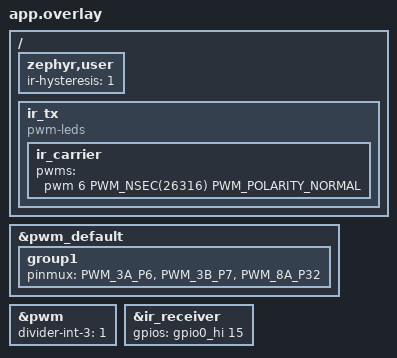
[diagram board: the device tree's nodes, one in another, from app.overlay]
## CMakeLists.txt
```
cmake_minimum_required(VERSION 3.20.0)
find_package(Zephyr REQUIRED HINTS $ENV{ZEPHYR_BASE})
project(ir_capture)
target_sources(app PRIVATE src/main.c src/ir_decode.c src/ir_seq.c src/ui.c
  src/slot_store.c)
```

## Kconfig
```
# Opcoes proprias do app. O resto do Kconfig vem do Zephyr.

mainmenu "zbook remote control"

config APP_IR_DEBUG
	bool "Imprimir toda captura IR no console"
	help
	  Imprime cada captura do receptor, dentro ou fora do modo gravar:
	  instante da primeira borda, intervalo desde a captura anterior,
	  duracoes brutas e o resultado de cada quadro decodificado
	  separadamente, com o tempo de decodificacao na placa.
	  Serve para diagnosticar controles que mandam varios quadros por
	  toque. A 115200 baud, a impressao trava o main por ~25 ms numa
	  captura tipica e ate ~130 ms numa de 200 bordas. Desligada, o
	  codigo nao vai para o binario.

config APP_IR_ROBUST_FALLBACK
	bool "Decodificador IR robusto como reserva do convencional"
	default y
	help
	  O decodificador tenta primeiro o caminho convencional (tempos
	  conferidos um a um, para o sinal limpo do receptor sem o
	  capacitor de 100 nF). Com esta opcao, um quadro que ele nao le
	  vai para o caminho robusto (blocos, esticamento e busca), feito
	  para o sinal distorcido. Desligada, so o convencional roda; serve
	  para comparar os dois sem mexer no codigo. A busca do robusto
	  precisa de CONFIG_MAIN_STACK_SIZE=8192.

source "Kconfig.zephyr"
```

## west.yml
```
manifest:
  remotes:
    - name: zephyrproject-rtos
      url-base: https://github.com/zephyrproject-rtos
    - name: zephyr-book
      url-base: https://github.com/zephyr-book
  projects:
    - name: zephyr
      remote: zephyrproject-rtos
      revision: 03b0b5443c7a760745826cc53c40e1986d753f86
      import: true
    - name: zbook
      remote: zephyr-book
      revision: 530df5dc6e51823b0eafb1f639ce86da6029fa8f
      path: modules/zbook
  self:
    path: zbook_remote_control
```

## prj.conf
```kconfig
CONFIG_GPIO=y
CONFIG_PWM=y
CONFIG_INPUT=y
CONFIG_LOG_PRINTK=n
# A busca do decodificador e recursiva (ate 33 niveis) e guarda as
# hipoteses de cada bloco na pilha: ~4 KB no pior caso.
CONFIG_MAIN_STACK_SIZE=8192

# Display OLED (SSD1306 por I2C) com o framebuffer de caracteres (CFB).
# A CFB aloca o buffer da tela (128 * 64 / 8 = 1 KB) com k_malloc.
CONFIG_DISPLAY=y
CONFIG_CHARACTER_FRAMEBUFFER=y
CONFIG_HEAP_MEM_POOL_SIZE=4096

# Slots na flash: subsistema settings com NVS na particao storage
# (zephyr,settings-partition da placa, ultimos 256 KB).
CONFIG_FLASH=y
CONFIG_FLASH_MAP=y
CONFIG_NVS=y
CONFIG_SETTINGS=y
CONFIG_SETTINGS_NVS=y
# Gravacoes cruas tem ate ~2 KB: 32 setores de 4 KB (128 KB dos 256 KB da
# particao). O NVS precisa de um setor livre para a coleta de lixo.
CONFIG_SETTINGS_NVS_SECTOR_COUNT=32

# Imprime toda captura IR (ver Kconfig). Para ligar sem mexer aqui:
#   west build -b zbook/rp2350b/m33 . -- -DCONFIG_APP_IR_DEBUG=y
CONFIG_APP_IR_DEBUG=n

# Caminho robusto do decodificador como reserva (ver Kconfig). Para
# comparar so com o convencional:
#   west build -b zbook/rp2350b/m33 . -- -DCONFIG_APP_IR_ROBUST_FALLBACK=n
CONFIG_APP_IR_ROBUST_FALLBACK=y
```

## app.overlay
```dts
/* Emissor IR no GPIO6 via PWM (slice 3, canal A) para gerar 38 kHz.
 * Vale para a ZBook P2. */

/* O GPIO6 deixa de ser um LED comum e passa a ser controlado pelo PWM. */
/delete-node/ &ir_emitter;

/* Conecta o GPIO6 ao PWM, mantendo os pinos que a placa ja usava. */
&pwm_default {
	group1 {
		pinmux = <PWM_3A_P6>, <PWM_3B_P7>, <PWM_8A_P32>;
	};
};

/* Divisor 1 no slice 3: o contador anda a 150 MHz, o que da
 * resolucao fina para os 38 kHz. */
&pwm {
	divider-int-3 = <1>;
};

/* Configuracao do pino do receptor (GPIO47). Variacoes testadas na
 * Parte A (docs/DEVLOG.md): sem pull, GPIO_PULL_UP e GPIO_PULL_DOWN. O
 * pull-down ficou porque dava o menor esticamento dos pulsos (~850 us).
 * Esse esticamento nao era do receptor: vinha de um capacitor de 100 nF
 * na linha, que nao devia estar ali. Sem o capacitor, fica entre 0 e
 * 20 us e o decodificador usa o caminho convencional; o caminho robusto
 * ficou como reserva. O pull-down foi mantido (nao foi medido de novo
 * sem o capacitor). */
&ir_receiver {
	gpios = <&gpio0_hi 15 (GPIO_ACTIVE_HIGH | GPIO_PULL_DOWN)>;
};

/ {
	/* Propriedades proprias da aplicacao, lidas no main.c com DT_PROP.
	 * ir-hysteresis: 1 liga o schmitt trigger do pino do receptor (padrao
	 * do RP2350), 0 desliga. O driver GPIO do Zephyr nao tem flag para
	 * isso, entao o main.c aplica o valor pelo Pico SDK. Desligada, a
	 * borda lenta do receptor gera bordas espurias e nenhum toque foi
	 * capturado; por isso fica ligada. (Medido com o capacitor de
	 * 100 nF na linha, que provavelmente deixava a borda lenta; sem ele,
	 * nao foi testado de novo.) */
	zephyr,user {
		ir-hysteresis = <1>;
	};

	ir_tx {
		compatible = "pwm-leds";

		/* Canal 6 = slice 3, canal A (GPIO6). Periodo de 26316 ns = 38 kHz. */
		ir_carrier: ir_carrier {
			pwms = <&pwm 6 PWM_NSEC(26316) PWM_POLARITY_NORMAL>;
		};
	};
};
```

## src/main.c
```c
#include <string.h>

#include <zephyr/drivers/gpio.h>
#include <zephyr/drivers/pwm.h>
#include <zephyr/kernel.h>

/* API do Pico SDK (hal_rpi_pico), usada so para a histerese do pino,
 * que o driver GPIO do Zephyr nao expoe. */
#include <hardware/gpio.h>
#include <hardware/structs/pads_bank0.h>

#include "ir_decode.h"
#include "ir_edges.h"
#include "ir_seq.h"
#include "slot_store.h"
#include "ui.h"

/* Bordas por captura. Um quadro NEC tem 68; ar-condicionado chega a
 * centenas (gravacao crua). */
#define MAX_EDGES IR_RAW_MAX

/* Mais quadros que isso numa captura sao ignorados (MAX_EDGES cabe ~3). */
#define MAX_FRAMES 8

/* Silencio que encerra uma captura. Menor que o intervalo entre os
 * quadros de um toque (~46 ms), para cada quadro chegar separado. */
#define END_OF_CAPTURE_MS 20

/* 1 imprime as duracoes brutas de cada captura no modo gravar. Com
 * CONFIG_APP_IR_DEBUG, elas saem sempre, na impressao de depuracao. */
#define PRINT_RAW 1

/* Histerese (schmitt trigger) do pino do receptor, escolhida no
 * app.overlay pela propriedade ir-hysteresis do no zephyr,user. O padrao
 * do RP2350 apos o reset e ligada. */
#define ZEPHYR_USER DT_PATH(zephyr_user)
#define IR_HYSTERESIS DT_PROP_OR(ZEPHYR_USER, ir_hysteresis, 1)

/* Receptor (entrada) e portadora do emissor (saida). */
static const struct gpio_dt_spec ir =
    GPIO_DT_SPEC_GET(DT_NODELABEL(ir_receiver), gpios);
static const struct pwm_dt_spec carrier =
    PWM_DT_SPEC_GET(DT_NODELABEL(ir_carrier));
static struct gpio_callback ir_cb;

/* Captura: preenchido pela interrupcao, pelo filtro do ir_edges.h, que
 * le o nivel do pino e apaga os intervalos da portadora. */
static volatile uint32_t edges[MAX_EDGES];
static struct ir_edges cap = {.t = edges, .max = MAX_EDGES};
static volatile uint32_t last_edge;
static uint32_t ir_pin; /* numero absoluto do pino (GPIO47) */
static uint32_t copy[MAX_EDGES];
static uint32_t durations[MAX_EDGES];

/* Junta os quadros de um toque numa sequencia (ir_seq.c). So os codigos
 * vao para os slots; os tempos sao remontados na hora de enviar. */
static struct ir_recorder rec;

/* Transmissao montada a partir da sequencia ou da gravacao crua. */
#define TX_MAX (IR_SEQ_TX_MAX > IR_RAW_MAX ? IR_SEQ_TX_MAX : IR_RAW_MAX)
static uint32_t tx_buf[TX_MAX];

/* Copia da gravacao crua pronta (grande demais para a pilha). */
static struct ir_raw raw_done;

/* Resultado de um quadro, guardado para a impressao de depuracao. */
struct frame_result {
  struct ir_span span;
  enum ir_status status;
  struct ir_code code;
  struct ir_decode_info info;
  uint32_t t_us;      /* inicio do quadro (primeira borda) */
  uint32_t decode_us; /* tempo do ir_decode_frame na placa */
};

static void on_edge(const struct device *dev, struct gpio_callback *cb,
                    uint32_t pins) {
  uint32_t now = k_cycle_get_32();

  /* Leitura direta do SIO (inline, poucos ciclos). */
  ir_edges_on_edge(&cap, now, gpio_get(ir_pin));
  last_edge = now;
}

/* Reproduz um sinal: nos pulsos liga a portadora (duty ~1/3),
 * nos espacos desliga. */
static void ir_send(const uint32_t *dur_us, int count) {
  /* Sem isso, o proprio receptor da placa capturaria o envio. */
  gpio_pin_interrupt_configure_dt(&ir, GPIO_INT_DISABLE);

  /* Evita que outra thread interrompa o envio no meio. */
  k_sched_lock();

  uint32_t t = k_cycle_get_32();

  for (int i = 0; i < count; i++) {
    bool pulse = (i % 2) == 0;

    pwm_set_pulse_dt(&carrier, pulse ? carrier.period / 3 : 0);

    /* Espera ate o instante exato do fim deste intervalo.
     * Usar um alvo absoluto evita acumular atraso. */
    t += k_us_to_cyc_ceil32(dur_us[i]);
    while ((int32_t)(k_cycle_get_32() - t) < 0) {
    }
  }
  pwm_set_pulse_dt(&carrier, 0);

  k_sched_unlock();

  /* Descarta o que tiver sido capturado e volta a escutar. */
  k_msleep(50);
  cap.n = 0;
  gpio_pin_interrupt_configure_dt(&ir, GPIO_INT_EDGE_BOTH);
}

/* Se a captura terminou (silencio de END_OF_CAPTURE_MS), copia as bordas
 * para out e devolve quantas sao; senao devolve 0.
 *
 * Tudo acontece com as interrupcoes travadas. Antes, o relogio era lido
 * primeiro e last_edge depois; se uma borda chegasse entre as duas
 * leituras, last_edge ficava maior que o "agora", a subtracao sem sinal
 * dava ~4 bilhoes e a captura era encerrada no meio do quadro. Com
 * irq_lock, on_edge nao roda entre as leituras, entao agora >= last_edge,
 * e a decisao de encerrar e a copia ficam consistentes: nenhuma borda
 * nova entra depois da decisao. */
static int take_capture(uint32_t *out) {
  int n = 0;
  unsigned int key = irq_lock();
  uint32_t idle = k_cycle_get_32() - last_edge;

  if (cap.n > 0 && k_cyc_to_ms_floor32(idle) >= END_OF_CAPTURE_MS) {
    n = cap.n;
    for (int i = 0; i < n; i++) {
      out[i] = edges[i];
    }
    cap.n = 0;
  }
  irq_unlock(key);
  return n;
}

/* Relogio do gravador: us de 32 bits, tirado do contador de ciclos de
 * 64 bits (da a volta a cada ~71 min, sem salto). */
static uint32_t now_us(void) {
  return (uint32_t)k_cyc_to_us_floor64(k_cycle_get_64());
}

/* Instante de uma borda no relogio do gravador. A interrupcao guarda so
 * os 32 bits de baixo do contador (que da a volta a cada ~28 s); a idade
 * da borda, medida contra o mesmo "agora", reconstroi os 64 bits. Assim
 * vale o horario em que o sinal chegou, nao a hora em que o main viu a
 * captura (que atrasa com o desenho da tela ou um printk). */
static uint32_t edge_time_us(uint32_t edge_cyc, uint64_t now_cyc) {
  uint32_t age = (uint32_t)now_cyc - edge_cyc;

  return (uint32_t)k_cyc_to_us_floor64(now_cyc - age);
}

/* Envia a sequencia de um slot gravado, com "Enviando..." na tela. */
static void send_slot(int slot) {
  const struct ir_seq *seq = ui_slot_sequence(slot);
  const uint16_t *raw;
  int raw_n = ui_slot_raw(slot, &raw);

  if (raw_n > 0 && raw_n <= (int)ARRAY_SIZE(tx_buf)) {
    uint32_t total = 0;

    for (int i = 0; i < raw_n; i++) {
      tx_buf[i] = raw[i];
      total += raw[i];
    }
    printk("Enviando \"%s / %s\" (%s, %d intervalos, %u ms)\n",
           ui_device_name(ui_device()), ui_slot_name(slot),
           ui_slot_source(slot) == UI_SRC_RECORDED ? "gravacao crua"
                                                   : "de fabrica",
           raw_n, total / 1000);
    ui_set_sending(slot);
    ui_draw();
    ir_send(tx_buf, raw_n);
    ui_set_sending(-1);
    printk("Enviado\n\n");
    return;
  }
  if (seq == NULL) {
    return;
  }
  int n = ir_seq_encode(seq, tx_buf, ARRAY_SIZE(tx_buf));

  if (n == 0) {
    printk("Slot \"%s\": sequencia invalida, nada enviado\n",
           ui_slot_name(slot));
    return;
  }
  printk("Enviando \"%s / %s\" (%s, %d codigo(s)):\n",
         ui_device_name(ui_device()), ui_slot_name(slot),
         ui_slot_source(slot) == UI_SRC_RECORDED ? "gravado" : "de fabrica",
         seq->count);
  for (int i = 0; i < seq->count; i++) {
    printk("  %s 0x%08X (+%u us)\n", ir_protocol_name(seq->codes[i].protocol),
           seq->codes[i].code, seq->gap_us[i]);
  }
  /* ir_send trava o escalonador, entao a tela e desenhada antes. */
  ui_set_sending(slot);
  ui_draw();
  ir_send(tx_buf, n);
  ui_set_sending(-1);
  printk("Enviado\n\n");
}

static void print_durations(const uint32_t *dur, int n) {
  printk("Bruto: %d intervalos\n", n);
  for (int i = 0; i < n; i++) {
    printk("%c%u ", (i % 2) ? '-' : '+', dur[i]);
    if ((i + 1) % 8 == 0) {
      printk("\n");
    }
  }
  printk("\n");
}

/* Mostra no console o que o gravador fez com um quadro. */
static void report_frame(const struct frame_result *f,
                         enum ir_rec_result r) {
  const struct ir_seq *seq = &rec.seq;

  switch (r) {
  case IR_REC_ADDED:
    printk("Gravado: %s 0x%08X (codigo %d, +%u us)\n",
           ir_protocol_name(f->code.protocol), f->code.code, seq->count,
           seq->gap_us[seq->count - 1]);
    break;
  case IR_REC_PENDING:
    printk("Quadro %s 0x%08X com pulso perdido: esperando confirmacao\n",
           ir_protocol_name(f->code.protocol), f->code.code);
    break;
  case IR_REC_CYCLE:
    printk("Codigo 0x%08X ja esta na sequencia (controle recomecou): "
           "ignorado\n", f->code.code);
    break;
  case IR_REC_FULL:
    printk("Sequencia cheia (%d codigos): 0x%08X ignorado\n", IR_SEQ_MAX,
           f->code.code);
    break;
  case IR_REC_LATE:
    printk("Quadro 0x%08X comecou depois da janela: ignorado\n",
           f->code.code);
    break;
  case IR_REC_REJECTED:
    printk("Quadro rejeitado: %s\n", ir_status_name(f->status));
    break;
  case IR_REC_SAME:
  case IR_REC_REPEAT:
    break;
  }
}

/* Impressao de depuracao de toda captura, com ou sem modo gravar
 * (CONFIG_APP_IR_DEBUG). Feita depois do gravador, para nao atrasar
 * nada que dependa de tempo; o gravador usa o horario das bordas. */
static void debug_capture(int n_edges_copied, int n, const struct frame_result *fr,
                          int frames, uint32_t t0_us) {
  static uint32_t count;
  static uint32_t prev_t0_us;
  static uint32_t prev_end_us;
  uint32_t end_us = t0_us + k_cyc_to_us_floor32(copy[n_edges_copied - 1] - copy[0]);

  count++;
  printk("== IR captura %u: t=%u ms", count, t0_us / 1000);
  if (count > 1) {
    printk(", +%u ms desde a anterior (silencio %u ms)",
           (t0_us - prev_t0_us) / 1000, (t0_us - prev_end_us) / 1000);
  }
  printk(", modo gravar: %s\n", ui_is_recording() ? "sim" : "nao");
  printk("Limite MAX_EDGES (%d bordas): %s\n", MAX_EDGES,
         n_edges_copied >= MAX_EDGES ? "SIM, captura cortada" : "nao");
  printk("Filtro: %u espacos de portadora apagados, %u bordas fora de "
         "ordem ignoradas (desde a partida)\n", cap.merged, cap.ignored);
  prev_t0_us = t0_us;
  prev_end_us = end_us;

  print_durations(durations, n);
  for (int f = 0; f < frames; f++) {
    const struct frame_result *r = &fr[f];

    printk("quadro %d: %d intervalos, +%u us: ", f + 1, r->span.len,
           r->t_us - t0_us);
    if (r->status == IR_OK) {
      printk("%s 0x%08X, esticamento %d us (%d a %d), pulsos perdidos %d",
             ir_protocol_name(r->code.protocol), r->code.code,
             r->info.stretch_avg_us, r->info.stretch_min_us,
             r->info.stretch_max_us, r->info.lost_pulses);
      printk(", %d passos, caminho %s", r->info.search_steps,
             r->info.path == IR_PATH_CONVENTIONAL ? "convencional"
                                                  : "robusto");
    } else {
      printk("%s", ir_status_name(r->status));
    }
    printk(", decodificado em %u us\n", r->decode_us);
  }
  printk("\n");
}

/* Separa a captura em quadros, decodifica cada um e entrega ao gravador.
 * O ir_decode para no primeiro quadro valido; aqui cada quadro conta,
 * porque se o main atrasar dois codigos diferentes podem cair na mesma
 * captura. */
static void handle_capture(int n_edges_copied) {
  static struct frame_result fr[MAX_FRAMES];
  struct ir_span spans[MAX_FRAMES];
  int n = n_edges_copied - 1;
  uint64_t now_cyc = k_cycle_get_64();
  bool recording = ui_is_recording();
  bool debug = IS_ENABLED(CONFIG_APP_IR_DEBUG);

  if (!recording && !debug) {
    return;
  }

  /* Converte instantes em duracoes: pulso, espaco, pulso... */
  for (int i = 0; i < n; i++) {
    durations[i] = k_cyc_to_us_floor32(copy[i + 1] - copy[i]);
  }
  if (PRINT_RAW && recording && !debug) {
    print_durations(durations, n);
  }

  int frames = ir_split_frames(durations, n, spans, MAX_FRAMES);

  for (int f = 0; f < frames; f++) {
    struct frame_result *r = &fr[f];
    uint32_t c0 = k_cycle_get_32();

    r->span = spans[f];
    r->status = ir_decode_frame(durations + spans[f].start, spans[f].len,
                                &r->code, &r->info);
    r->decode_us = k_cyc_to_us_floor32(k_cycle_get_32() - c0);
    /* durations[i] comeca na borda copy[i]. */
    r->t_us = edge_time_us(copy[spans[f].start], now_cyc);

    if (recording) {
      enum ir_rec_result res = ir_rec_frame(
          &rec, r->status, &r->code,
          r->status == IR_OK ? r->info.lost_pulses : 0, r->t_us);

      if (!debug && r->status == IR_OK) {
        printk("Quadro: %s 0x%08X, esticamento %d us (%d a %d), "
               "pulsos perdidos %d\n",
               ir_protocol_name(r->code.protocol), r->code.code,
               r->info.stretch_avg_us, r->info.stretch_min_us,
               r->info.stretch_max_us, r->info.lost_pulses);
      }
      report_frame(r, res);
    }
  }

  /* A captura inteira vai para a gravacao crua, que so vale se nenhum
   * codigo for reconhecido no toque. */
  if (recording) {
    ir_rec_capture(&rec, durations, n, edge_time_us(copy[0], now_cyc),
                   n_edges_copied >= MAX_EDGES);
  }
  if (debug) {
    debug_capture(n_edges_copied, n, fr, frames,
                  edge_time_us(copy[0], now_cyc));
  }
}

/* Confere o gravador: aviso de falha adiado e fim da janela. */
static void poll_recorder(void) {
  struct ir_seq seq;
  bool suspect = false;

  switch (ir_rec_poll(&rec, now_us(), &seq, &suspect)) {
  case IR_REC_POLL_WARN:
    printk("Aviso: sinal nao reconhecido (%s); nada foi gravado.\n"
           "Tente de novo com o controle a uns 30 cm a 1 m da placa.\n\n",
           rec.warn_reason);
    ui_record_failed();
    break;

  case IR_REC_POLL_DONE: {
    int slot = ui_record_sequence(&seq);

    if (slot < 0) {
      break;
    }
    printk("Slot \"%s\" gravado com %d codigo(s)\n", ui_slot_name(slot),
           seq.count);
    if (suspect) {
      printk("Aviso: um quadro perto deste toque falhou; a sequencia pode "
             "estar incompleta.\nSe o aparelho nao reagir, grave de novo.\n");
    }
    int err = slot_store_save(ui_device(), slot, &seq);

    if (err != 0) {
      printk("Aviso: falha ao salvar na flash (%d); o slot vale ate "
             "reiniciar\n", err);
    }
    printk("\n");
    break;
  }

  case IR_REC_POLL_RAW: {
    const struct ir_raw *raw = ir_rec_raw(&rec);

    raw_done.n = raw->n;
    memcpy(raw_done.d, raw->d, sizeof(raw->d[0]) * raw->n);
    ir_rec_reset(&rec);

    int slot = ui_record_raw(&raw_done);

    if (slot < 0) {
      printk("Gravacao crua nao salva (%d intervalos): sinal invalido ou "
             "sem espaco (%d gravacoes cruas no maximo)\n\n", raw_done.n,
             UI_RAW_SLOTS);
      break;
    }
    printk("Slot \"%s\" gravado cru: %d intervalos (protocolo nao "
           "reconhecido; reenvia os tempos como chegaram)\n",
           ui_slot_name(slot), raw_done.n);
    if (suspect) {
      printk("Aviso: o toque passou de %d intervalos e foi cortado.\n",
             IR_RAW_MAX);
    }
    int err = slot_store_save_raw(ui_device(), slot, &raw_done);

    if (err != 0) {
      printk("Aviso: falha ao salvar na flash (%d); o slot vale ate "
             "reiniciar\n", err);
    }
    printk("\n");
    break;
  }

  case IR_REC_POLL_NONE:
    break;
  }
}

static void on_slot_loaded(int dev, int slot, const struct ir_seq *seq) {
  ui_restore_slot(dev, slot, seq);
  printk("Flash: \"%s / %s\" gravado com %d codigo(s)\n",
         ui_device_name(dev), ui_device_slot_name(dev, slot),
         seq->count);
}

static void on_raw_loaded(int dev, int slot, const struct ir_raw *raw) {
  ui_restore_raw(dev, slot, raw);
  printk("Flash: \"%s / %s\" gravado cru (%d intervalos)\n",
         ui_device_name(dev), ui_device_slot_name(dev, slot), raw->n);
}

static int saved_device;

static void on_device_loaded(int dev) {
  ui_set_device(dev);
  saved_device = dev;
}

static const struct slot_store_cb store_cb = {
    .num_devices = IR_LIB_NUM_DEVICES,
    .max_slots = IR_LIB_MAX_SLOTS,
    /* Os slots das versoes anteriores (um aparelho so) vao para "Livre". */
    .legacy_device = IR_LIB_LIVRE,
    .on_slot = on_slot_loaded,
    .on_raw = on_raw_loaded,
    .on_device = on_device_loaded,
};

/* Leva para a flash o que a interface mudou: aparelho escolhido e
 * gravacoes apagadas. */
static void sync_store(void) {
  int dev, slot;

  if (ui_device() != saved_device) {
    saved_device = ui_device();
    if (slot_store_save_device(saved_device) != 0) {
      printk("Aviso: falha ao salvar o aparelho na flash\n");
    }
  }
  if (ui_take_erased(&dev, &slot)) {
    int err = slot_store_erase(dev, slot);

    /* -ENOENT: a gravacao ainda nao tinha chegado a flash. */
    if (err != 0 && err != -ENOENT) {
      printk("Aviso: falha ao apagar da flash (%d)\n", err);
    }
    printk("\n");
  }
}

/* Numero absoluto do pino (0..47): o banco gpio0_hi comeca no GPIO32. */
static uint32_t ir_pad_pin(void) {
  return ir.pin + (ir.port == DEVICE_DT_GET(DT_NODELABEL(gpio0_hi)) ? 32 : 0);
}

static void print_receiver_config(void) {
  uint32_t pin = ir_pad_pin();
  uint32_t pad = pads_bank0_hw->io[pin];

  printk("Receptor GPIO%u: pull %s, histerese %s, nivel em repouso %d\n",
         pin,
         (pad & PADS_BANK0_GPIO0_PUE_BITS)   ? "up"
         : (pad & PADS_BANK0_GPIO0_PDE_BITS) ? "down"
                                             : "nenhum",
         (pad & PADS_BANK0_GPIO0_SCHMITT_BITS) ? "ligada" : "desligada",
         gpio_pin_get_raw(ir.port, ir.pin));
}

int main(void) {
  if (!gpio_is_ready_dt(&ir) || !pwm_is_ready_dt(&carrier)) {
    printk("Receptor ou PWM nao esta pronto\n");
    return 0;
  }
  pwm_set_pulse_dt(&carrier, 0);

  /* GPIO_INPUT se junta as flags do devicetree (pull-up/down). */
  if (gpio_pin_configure_dt(&ir, GPIO_INPUT) < 0 ||
      gpio_pin_interrupt_configure_dt(&ir, GPIO_INT_EDGE_BOTH) < 0) {
    printk("Falha ao configurar o pino do receptor\n");
    return 0;
  }
  gpio_set_input_hysteresis_enabled(ir_pad_pin(), IR_HYSTERESIS);
  ir_pin = ir_pad_pin();
  cap.merge = k_us_to_cyc_ceil32(IR_EDGE_MERGE_US);
  gpio_init_callback(&ir_cb, on_edge, BIT(ir.pin));
  gpio_add_callback(ir.port, &ir_cb);

  if (ui_init() < 0) {
    printk("Display nao esta pronto; seguindo sem tela\n");
  }
  int loaded = slot_store_init(&store_cb);

  if (loaded < 0) {
    printk("Flash: settings indisponivel (%d); gravacoes so na RAM\n",
           loaded);
  } else {
    printk("Flash: %d gravacao(oes) carregada(s)\n", loaded);
  }
  printk("Aparelho: %s\n", ui_device_name(ui_device()));
  ui_draw();

  print_receiver_config();
  if (IS_ENABLED(CONFIG_APP_IR_DEBUG)) {
    printk("CONFIG_APP_IR_DEBUG ligada: toda captura e impressa\n");
  }
  printk("Gire o encoder para escolher um slot. Clique envia; segure\n"
         "0,8 s para gravar. No nome do aparelho (acima do 1o slot), o\n"
         "clique troca de aparelho. BUTTON0..3 enviam os slots 1..4.\n"
         "Na lista: fb = codigo de fabrica, gr = gravado, -- = vazio.\n\n");

  bool was_recording = false;

  while (1) {
    struct ui_event evt;

    /* Espera ate 10 ms por um evento de entrada; o timeout faz o papel do
     * tick que verifica a captura. Depois esvazia o que mais tiver na
     * fila, para girar rapido nao gerar um redesenho por clique. */
    if (k_msgq_get(&ui_msgq, &evt, K_MSEC(10)) == 0) {
      do {
        int slot = ui_handle_event(&evt);

        if (slot >= 0) {
          send_slot(slot);
        }
      } while (k_msgq_get(&ui_msgq, &evt, K_NO_WAIT) == 0);
    }
    ui_tick();

    /* Entrar ou sair do modo gravar (inclusive cancelar) zera o
     * gravador: nada de uma gravacao anterior vale depois. */
    bool recording = ui_is_recording();

    if (recording != was_recording) {
      ir_rec_reset(&rec);
      was_recording = recording;
    }

    /* A captura sempre e retirada do buffer; handle_capture so
     * decodifica no modo gravar (ou com a depuracao ligada). O gravador
     * e conferido depois, para um quadro que comecou dentro da janela
     * entrar mesmo que o main o veja depois do prazo. */
    int n = take_capture(copy);

    if (n >= 2) {
      handle_capture(n);
    }
    if (recording) {
      poll_recorder();
    }
    sync_store();
    ui_draw();
  }
  return 0;
}
```

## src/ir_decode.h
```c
/* Decodificador de IR hibrido para NEC, Samsung32 e Coolix.
 *
 * C puro, sem dependencias do Zephyr: compila no PC (testes) e na placa.
 *
 * Entrada: duracoes em microssegundos, alternando pulso (portadora
 * ligada), espaco, pulso... sempre comecando por um pulso.
 *
 * Primeiro tenta o caminho convencional (cada tempo conferido contra o
 * nominal), que le o sinal limpo do receptor. Se ele nao ler o quadro, o
 * caminho robusto (reserva, CONFIG_APP_IR_ROBUST_FALLBACK) le NEC e
 * Samsung32 mesmo com os pulsos esticados e os espacos encurtados por uma
 * quantidade variavel (o "esticamento"), usando o periodo entre o inicio
 * de um pulso e o inicio do seguinte, que se preserva. O esticamento era
 * causado por um capacitor de 100 nF na linha do receptor, ja removido;
 * sem ele, fica entre 0 e 20 us. Detalhes em ir_decode.c.
 */
#ifndef IR_DECODE_H
#define IR_DECODE_H

#include <stdint.h>

/* Espaco acima disso separa dois quadros. */
#define IR_FRAME_GAP_US 10000

/* Quadro ideal: cabecalho (2) + 32 bits (64) + pulso final (1). */
#define IR_FRAME_LEN 67

/* Quadro do Coolix: cabecalho (2) + 48 bits (96) + pulso final (1). */
#define IR_COOLIX_FRAME_LEN 99

/* Maior sequencia que ir_encode gera (dois quadros e o intervalo). */
#define IR_ENCODE_MAX (2 * IR_COOLIX_FRAME_LEN + 1)

/* Maior quadro que ir_encode_frame gera. */
#define IR_ENCODE_FRAME_MAX IR_COOLIX_FRAME_LEN

enum ir_protocol {
  IR_PROTO_NONE = 0,
  IR_PROTO_NEC,
  IR_PROTO_SAMSUNG32,
  /* Ar-condicionado da familia Midea (Springer Midea, Carrier, Comfee,
   * Beko, Toshiba...): 24 bits de estado, cada byte seguido do seu
   * inverso. Envio e gravacao: so o caminho convencional le este
   * protocolo (o cabecalho cai na tolerancia do Samsung32; quem separa e
   * o numero de intervalos, 99 ou 199 contra 67). Gravacoes viram uma
   * sequencia normal de um codigo, igual a da biblioteca. Com o sinal
   * distorcido (receptor com o capacitor), o convencional nao le e a
   * gravacao continua crua. */
  IR_PROTO_COOLIX,
};

enum ir_status {
  IR_OK = 0,
  IR_REPEAT,        /* codigo de repeticao do NEC (botao segurado) */
  IR_ERR_HEADER,    /* nao comeca com um cabecalho conhecido */
  IR_ERR_TRUNCATED, /* quadro cortado: termina num espaco */
  IR_ERR_DECODE,    /* nenhuma interpretacao com 32 bits coerentes */
  IR_ERR_CHECK,     /* ha 32 bits, mas nenhum passa na validacao */
  IR_ERR_AMBIGUOUS, /* mais de um codigo valido possivel */
};

struct ir_code {
  enum ir_protocol protocol;
  /* Bits na ordem em que chegam, o primeiro no bit 31 (MSB primeiro).
   * Ex.: liga/desliga Samsung = 0xE0E040BF. */
  uint32_t code;
};

/* Caminho do decodificador que leu o quadro (ver ir_decode.c). */
enum ir_decode_path {
  IR_PATH_NONE = 0,
  IR_PATH_CONVENTIONAL, /* tempos conferidos um a um, sinal limpo */
  IR_PATH_ROBUST,       /* blocos e busca, sinal distorcido */
};

/* Informacoes extras de uma decodificacao bem sucedida. No caminho
 * convencional, lost_pulses = 0, candidates = 1 e search_steps = 0. */
struct ir_decode_info {
  int32_t stretch_avg_us; /* esticamento medio estimado no quadro */
  int32_t stretch_min_us;
  int32_t stretch_max_us;
  int lost_pulses;  /* pulsos que a leitura escolhida supoe perdidos */
  int candidates;   /* leituras com 32 bits examinadas */
  int search_steps; /* passos da busca (mede o custo da decodificacao) */
  enum ir_decode_path path;
};

/* Trecho [start, start + len) de um vetor de duracoes. */
struct ir_span {
  int start;
  int len;
};

/* Separa uma captura em quadros nos espacos maiores que IR_FRAME_GAP_US.
 * Devolve quantos quadros foram escritos em spans (no maximo max). */
int ir_split_frames(const uint32_t *dur, int n, struct ir_span *spans,
                    int max);

/* Decodifica um unico quadro: caminho convencional e, se ele nao ler,
 * o robusto (se ligado). info pode ser NULL; info->path diz qual leu. */
enum ir_status ir_decode_frame(const uint32_t *dur, int n,
                               struct ir_code *out,
                               struct ir_decode_info *info);

/* Separa a captura em quadros e devolve o primeiro que decodificar.
 * Se nenhum decodificar, devolve o erro do ultimo quadro. */
enum ir_status ir_decode(const uint32_t *dur, int n, struct ir_code *out,
                         struct ir_decode_info *info);

/* Monta a transmissao com os tempos ideais, como o controle original
 * faria num toque: Samsung32 envia o quadro duas vezes; NEC envia o
 * quadro e um codigo de repeticao. Ambos a cada 108 ms.
 * Devolve o numero de duracoes escritas, ou 0 se nao couber. */
int ir_encode(const struct ir_code *code, uint32_t *dur, int max);

/* Monta um unico quadro ideal, sem repeticao. Usado para enviar
 * sequencias de codigos diferentes (ex.: projetor Epson).
 * Devolve o tamanho do quadro (IR_FRAME_LEN, ou IR_COOLIX_FRAME_LEN), ou
 * 0 se nao couber ou o protocolo e desconhecido. */
int ir_encode_frame(const struct ir_code *code, uint32_t *dur, int max);

/* Duracao do quadro ideal, do inicio do cabecalho ao fim do pulso
 * final, em us. 0 se o protocolo e desconhecido. */
uint32_t ir_frame_duration_us(const struct ir_code *code);

/* Valida o codigo de 32 bits segundo o protocolo. */
int ir_code_is_valid(enum ir_protocol protocol, uint32_t code);

const char *ir_protocol_name(enum ir_protocol protocol);
const char *ir_status_name(enum ir_status status);

#endif /* IR_DECODE_H */
```

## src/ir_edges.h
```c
/* Filtro de bordas do receptor, chamado pela interrupcao do GPIO47.
 *
 * O que o log da placa mostrou (06/11/2026): com alguns controles (o do
 * projetor Epson), o pino nao recebe so o envelope do sinal, mas a propria
 * portadora de ~38-40 kHz: uma borda a cada ~13 us. Isso causava:
 *
 *   - "sem cabecalho" e "Limite MAX_EDGES: SIM": o pulso de 9 ms do
 *     cabecalho virava ~350 pulsinhos de ~13 us, e as 200 bordas do buffer
 *     acabavam em ~2,5 ms;
 *   - "tempos incoerentes": com bordas tao rapidas, a interrupcao as vezes
 *     perde uma, a contagem pulso/espaco inverte e todo o resto do quadro
 *     sai trocado (pulsos viram espacos).
 *
 * O filtro faz a demodulacao em software:
 *
 *   1. Le o nivel do pino em cada borda, em vez de supor que as bordas
 *      alternam. Se o nivel nao bate com o esperado, uma borda se perdeu
 *      (um pico mais rapido que a interrupcao): a alternancia pulso/espaco
 *      nunca se perde, e um pulsinho de portadora logo depois da descida
 *      estende o pulso ate ele.
 *   2. Um espaco menor que IR_EDGE_MERGE_US e um intervalo da portadora,
 *      nao um espaco do protocolo: a descida e apagada e o pulso continua.
 *
 * Os espacos do protocolo tem centenas de us. Os curtos que o
 * decodificador ainda aceita (bit 1 com esticamento perto do maximo de
 * 1650 us) tem pelo menos ~40 us; os intervalos de portadora medidos
 * ficaram entre 6 e 28 us.
 *
 * C puro e so com inline: compila na placa e nos testes do PC.
 */
#ifndef IR_EDGES_H
#define IR_EDGES_H

#include <stdbool.h>
#include <stdint.h>

#define IR_EDGE_MERGE_US 40

struct ir_edges {
  volatile uint32_t *t; /* instantes: subida, descida, subida... */
  int max;
  volatile int n;
  uint32_t merge;      /* IR_EDGE_MERGE_US no relogio de t */
  uint32_t ignored;    /* bordas que nao bateram com o nivel */
  uint32_t merged;     /* espacos de portadora apagados */
};

/* Trata uma borda: now no mesmo relogio de t, high = nivel lido no pino
 * logo depois da borda. */
static inline void ir_edges_on_edge(struct ir_edges *e, uint32_t now,
                                    bool high) {
  int n = e->n;
  /* Indices pares sao subidas (inicio de pulso), impares, descidas. */
  bool expect_high = (n % 2) == 0;

  if (high != expect_high) {
    if (n == 0) {
      return; /* a captura comeca numa subida */
    }
    /* Uma borda se perdeu: a interrupcao rodou depois de o pino ja ter
     * voltado. No meio de um pulso (esperava descida, pino alto), foi um
     * intervalo de portadora mais curto que a interrupcao: o pulso
     * continua. No meio de um espaco (esperava subida, pino baixo), houve
     * um pulsinho de portadora que ja acabou: se ele veio logo depois da
     * descida registrada, o pulso foi ate agora. */
    if (expect_high && now - e->t[n - 1] < e->merge) {
      e->t[n - 1] = now;
      e->merged++;
    } else {
      e->ignored++;
    }
    return;
  }
  if (expect_high && n > 0 && now - e->t[n - 1] < e->merge) {
    /* Espaco curto demais: era a portadora. O pulso continua. */
    e->n = n - 1;
    e->merged++;
    return;
  }
  if (n < e->max) {
    e->t[n] = now;
    e->n = n + 1;
  }
}

#endif /* IR_EDGES_H */
```

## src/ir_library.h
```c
/* Banco de codigos de fabrica: aparelhos e seus botoes.
 *
 * Cada aparelho tem uma lista de slots. Um slot pode ter um codigo de
 * fabrica (daqui) e/ou uma gravacao feita na placa; a gravacao tem
 * prioridade. Slot sem nenhum dos dois esta vazio e precisa ser gravado.
 *
 * Fonte dos codigos: Flipper-IRDB (github.com/Lucaslhm/Flipper-IRDB,
 * commit d126fb1), pastas TVs/Samsung (60 arquivos) e Projectors/Epson
 * (24 arquivos). Para cada botao foi usado o codigo mais comum entre os
 * arquivos. O Flipper guarda endereco e comando com o bit menos
 * significativo primeiro; aqui os bytes estao na ordem de chegada (MSB
 * primeiro), como o ir_decode devolve: Samsung32 endereco 0x07, comando
 * 0x02 -> 0xE0E040BF.
 *
 * Conferido com a placa: Samsung Ligar 0xE0E040BF e Vol+ 0xE0E0E01F
 * (log de 06/11/2026) e Epson Ligar 0xC1AA09F6 (DEVLOG_EPSON.md).
 *
 * Epson: o controle manda, a cada toque, 0x81C00FF0 e depois o codigo do
 * botao, 108 ms depois (DEVLOG_EPSON.md). No Flipper-IRDB o 0x81C00FF0
 * aparece no lugar de varios botoes diferentes, o que confirma que ele e
 * um prefixo comum. Aqui cada botao do Epson e enviado assim, igual ao
 * controle original.
 *
 * Dados constantes, so com inline: incluido pelo ui.c e pelos testes.
 */
#ifndef IR_LIBRARY_H
#define IR_LIBRARY_H

#include "ir_philco_data.h"
#include "ir_seq.h"

#define IR_LIB_MAX_SLOTS 12

/* Nomes de slot: no maximo 9 caracteres (cabe "nome   gr" em 12). */
#define IR_LIB_SLOT_NAME_MAX 9
/* Nome do aparelho: no maximo 12 caracteres (a linha do cabecalho). */
#define IR_LIB_DEVICE_NAME_MAX 12

struct ir_lib_slot {
  const char *name;
  struct ir_seq seq; /* seq.count == 0: sem codigo de fabrica */
  /* Codigo de fabrica como tempos prontos (pulso, espaco, ..., pulso),
   * para protocolos longos de ar-condicionado. NULL: nao tem. */
  const uint16_t *raw;
  uint16_t raw_n;
};

struct ir_lib_device {
  const char *name;
  int n_slots;
  struct ir_lib_slot slots[IR_LIB_MAX_SLOTS];
};

#define IR_LIB_SAMSUNG(c)                                                 \
  {.count = 1, .codes = {{IR_PROTO_SAMSUNG32, (c)}}, .gap_us = {0}}

#define IR_LIB_EPSON_PREFIX 0x81C00FF0u
#define IR_LIB_EPSON_GAP_US 108000u
#define IR_LIB_EPSON(c)                                                   \
  {.count = 2,                                                            \
   .codes = {{IR_PROTO_NEC, IR_LIB_EPSON_PREFIX}, {IR_PROTO_NEC, (c)}},   \
   .gap_us = {0, IR_LIB_EPSON_GAP_US}}

#define IR_LIB_COOLIX(c)                                                  \
  {.count = 1, .codes = {{IR_PROTO_COOLIX, (c)}}, .gap_us = {0}}

#define IR_LIB_NONE {.count = 0}

#define IR_LIB_RAW(name, arr)                                             \
  {(name), IR_LIB_NONE, (arr), (uint16_t)(sizeof(arr) / sizeof((arr)[0]))}

enum {
  IR_LIB_TV_SAMSUNG = 0,
  IR_LIB_PROJ_EPSON,
  /* Os indices ficam na flash (remote/d<D>s<S>, remote/dev): aparelhos
   * novos entram sempre no fim. */
  IR_LIB_LIVRE,
  IR_LIB_AR_MIDEA,
  IR_LIB_AR_PHILCO,
  IR_LIB_NUM_DEVICES,
};

static const struct ir_lib_device ir_lib_devices[IR_LIB_NUM_DEVICES] = {
    [IR_LIB_TV_SAMSUNG] =
        {
            .name = "TV Samsung",
            .n_slots = 12,
            .slots =
                {
                    {"Ligar", IR_LIB_SAMSUNG(0xE0E040BF)},   /* 35 de 48 */
                    {"Vol +", IR_LIB_SAMSUNG(0xE0E0E01F)},   /* 44 de 45 */
                    {"Vol -", IR_LIB_SAMSUNG(0xE0E0D02F)},   /* 41 de 43 */
                    {"Canal +", IR_LIB_SAMSUNG(0xE0E048B7)}, /* 35 de 38 */
                    {"Canal -", IR_LIB_SAMSUNG(0xE0E008F7)}, /* 35 de 38 */
                    {"Mudo", IR_LIB_SAMSUNG(0xE0E0F00F)},    /* 46 de 47 */
                    {"Entrada", IR_LIB_SAMSUNG(0xE0E0807F)}, /* 32 de 35 */
                    {"Menu", IR_LIB_SAMSUNG(0xE0E058A7)},    /* 28 de 29 */
                    {"Cima", IR_LIB_SAMSUNG(0xE0E006F9)},    /* 38 de 41 */
                    {"Baixo", IR_LIB_SAMSUNG(0xE0E08679)},   /* 37 de 41 */
                    {"OK", IR_LIB_SAMSUNG(0xE0E016E9)},      /* 19 de 21 */
                    {"Voltar", IR_LIB_SAMSUNG(0xE0E01AE5)},  /* 29 de 29 */
                },
        },
    [IR_LIB_PROJ_EPSON] =
        {
            .name = "Proj. Epson",
            .n_slots = 10,
            .slots =
                {
                    {"Ligar", IR_LIB_EPSON(0xC1AA09F6)},   /* 15 de 15 */
                    {"Entrada", IR_LIB_EPSON(0xC1AA31CE)}, /* Source Search */
                    {"Vol +", IR_LIB_EPSON(0xC1AA19E6)},
                    {"Vol -", IR_LIB_EPSON(0xC1AA9966)},
                    {"Mudo", IR_LIB_EPSON(0xC1AAC936)},    /* A/V Mute */
                    {"Menu", IR_LIB_EPSON(0xC1AA59A6)},
                    {"Cima", IR_LIB_EPSON(0xC1AA0DF2)},
                    {"Baixo", IR_LIB_EPSON(0xC1AA4DB2)},
                    {"OK", IR_LIB_EPSON(0xC1AAA15E)},      /* Enter */
                    {"Voltar", IR_LIB_EPSON(0xC1AA21DE)},  /* Esc */
                },
        },
    /* Ar-condicionado da familia Midea Carrier (Springer Midea, Midea,
     * Carrier, Comfee) com controle do protocolo Coolix (IRremoteESP8266:
     * controles Midea RG51/RG52/RG57K, Beko, Toshiba, Tokio...). Cada
     * comando e o estado inteiro: "Frio 22" liga, poe em frio, 22 graus,
     * ventilador automatico.
     *
     * Estado de 24 bits (ir_Coolix.h): 0xB2, depois ventilador << 5 |
     * sensor 0x1F, depois temperatura << 4 | modo << 2. Frio = 0,
     * ventilador automatico = 0b101 (0xBF), temperatura pela tabela
     * kCoolixTempMap. Conferidos com capturas cruas do Flipper-IRDB
     * (ACs/): Desligar em 11 arquivos de marcas diferentes, Frio 18 a 24 e
     * Ventilar no Timberk e no Ballu.
     *
     * Atencao: alguns Midea usam outro protocolo (Midea de 48 bits,
     * controles RG57A/RG57H/RG66/RG10). Se estes nao funcionarem, grave
     * por cima: um controle Coolix e lido pelo caminho convencional do
     * decodificador e vira um codigo Coolix comum; um de outro protocolo
     * vira gravacao crua. */
    [IR_LIB_AR_MIDEA] =
        {
            .name = "Ar Midea",
            .n_slots = 10,
            .slots =
                {
                    {"Desligar", IR_LIB_COOLIX(0xB27BE0)},
                    {"Frio 18", IR_LIB_COOLIX(0xB2BF10)},
                    {"Frio 20", IR_LIB_COOLIX(0xB2BF20)},
                    {"Frio 22", IR_LIB_COOLIX(0xB2BF70)},
                    {"Frio 23", IR_LIB_COOLIX(0xB2BF50)},
                    {"Frio 24", IR_LIB_COOLIX(0xB2BF40)},
                    {"Frio 26", IR_LIB_COOLIX(0xB2BFD0)},
                    {"Auto 25", IR_LIB_COOLIX(0xB21FC8)},
                    {"Ventilar", IR_LIB_COOLIX(0xB2BFE4)},
                    {"Oscilar", IR_LIB_COOLIX(0xB26BE0)},
                },
        },
    /* Ar-condicionado Philco: SmartIR (codes/climate/3000.json, 409
     * codigos aprendidos com Broadlink). Quadro unico: cabecalho
     * 9000/4500, 15 bytes com o bit menos significativo primeiro,
     * ultimo byte = soma dos nibbles dos outros. Gerado por
     * tools/gen_philco.py (ir_philco_data.h), que confere o formato e o
     * checksum dos 409. Ventilador automatico, sem oscilar, salvo
     * "22 oscila". */
    [IR_LIB_AR_PHILCO] =
        {
            .name = "Ar Philco",
            .n_slots = 10,
            .slots =
                {
                    IR_LIB_RAW("Desligar", ir_philco_raw_0),
                    IR_LIB_RAW("Frio 18", ir_philco_raw_1),
                    IR_LIB_RAW("Frio 20", ir_philco_raw_2),
                    IR_LIB_RAW("Frio 22", ir_philco_raw_3),
                    IR_LIB_RAW("Frio 23", ir_philco_raw_4),
                    IR_LIB_RAW("Frio 24", ir_philco_raw_5),
                    IR_LIB_RAW("Frio 26", ir_philco_raw_6),
                    IR_LIB_RAW("22 oscila", ir_philco_raw_7),
                    IR_LIB_RAW("Auto 24", ir_philco_raw_8),
                    IR_LIB_RAW("Quente 24", ir_philco_raw_9),
                },
        },
    /* Sem codigos de fabrica: so gravacoes, para qualquer aparelho (e
     * para os slots gravados pelas versoes anteriores do firmware). */
    [IR_LIB_LIVRE] =
        {
            .name = "Livre",
            .n_slots = 8,
            .slots =
                {
                    {"Ligar", IR_LIB_NONE},   {"Vol +", IR_LIB_NONE},
                    {"Vol -", IR_LIB_NONE},   {"Canal +", IR_LIB_NONE},
                    {"Canal -", IR_LIB_NONE}, {"Mudo", IR_LIB_NONE},
                    {"Entrada", IR_LIB_NONE}, {"Menu", IR_LIB_NONE},
                },
        },
};

#endif /* IR_LIBRARY_H */
```

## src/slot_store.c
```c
/* Gravacoes na flash. Ver slot_store.h. */
#include "slot_store.h"

#include <zephyr/kernel.h>
#include <zephyr/settings/settings.h>
#include <zephyr/storage/flash_map.h>

#define STORE_PARTITION DT_FIXED_PARTITION_ID(DT_CHOSEN(zephyr_settings_partition))

#define STORE_ROOT "remote"

static const struct slot_store_cb *cbs;
static int loaded;

/* Buffers grandes fora da pilha (so a thread do main usa). */
static uint8_t store_buf[IR_RAW_STORE_MAX];
static struct ir_raw raw_tmp;

/* Le "<num>" no inicio de s; devolve o numero e avanca s, ou -1. */
static int parse_num(const char **s) {
  int v = 0, digits = 0;

  while (**s >= '0' && **s <= '9' && digits < 3) {
    v = v * 10 + (**s - '0');
    (*s)++;
    digits++;
  }
  return digits > 0 ? v : -1;
}

/* Nome relativo -> aparelho e slot. "d1s3" ou o antigo "s3". */
static bool parse_slot_key(const char *name, int *dev, int *slot) {
  const char *p = name;

  if (*p == 'd') {
    p++;
    *dev = parse_num(&p);
    if (*dev < 0 || *p != 's') {
      return false;
    }
  } else if (*p == 's') {
    *dev = cbs->legacy_device;
  } else {
    return false;
  }
  p++;
  *slot = parse_num(&p);
  return *slot >= 0 && *p == '\0' && *dev < cbs->num_devices &&
         *slot < cbs->max_slots;
}

static int on_set(const char *name, size_t len, settings_read_cb read_cb,
                  void *cb_arg) {
  uint8_t *buf = store_buf;
  const char *next;
  int dev, slot;

  if (settings_name_steq(name, "dev", &next) && next == NULL) {
    uint8_t d;

    if (len == 1 && read_cb(cb_arg, &d, 1) == 1 && d < cbs->num_devices &&
        cbs->on_device != NULL) {
      cbs->on_device(d);
    }
    return 0;
  }
  if (!parse_slot_key(name, &dev, &slot)) {
    return 0; /* chave desconhecida: ignora */
  }
  if (len > sizeof(store_buf)) {
    printk("Flash: %s com tamanho invalido (%u), ignorado\n", name,
           (unsigned int)len);
    return 0;
  }
  ssize_t n = read_cb(cb_arg, buf, len);
  struct ir_seq seq;

  if (n > 0 && ir_store_version(buf, (int)n) == IR_RAW_STORE_VERSION) {
    if (ir_raw_unpack(buf, (int)n, &raw_tmp) != 0) {
      printk("Flash: %s invalido, ignorado\n", name);
      return 0;
    }
    if (cbs->on_raw != NULL) {
      cbs->on_raw(dev, slot, &raw_tmp);
    }
    loaded++;
    return 0;
  }
  if (n < 0 || ir_seq_unpack(buf, (int)n, &seq) != 0) {
    printk("Flash: %s invalido, ignorado\n", name);
    return 0;
  }
  if (cbs->on_slot != NULL) {
    cbs->on_slot(dev, slot, &seq);
  }
  loaded++;
  return 0;
}

SETTINGS_STATIC_HANDLER_DEFINE(remote, STORE_ROOT, NULL, on_set, NULL, NULL);

/* Apaga a particao inteira. So quando o NVS nao consegue montar: os
 * dados ja estao ilegiveis (por exemplo, restos de outro firmware nos
 * setores que o NVS passou a usar). */
static int format_partition(void) {
  const struct flash_area *fa;
  int err = flash_area_open(STORE_PARTITION, &fa);

  if (err != 0) {
    return err;
  }
  err = flash_area_erase(fa, 0, fa->fa_size);
  flash_area_close(fa);
  return err;
}

int slot_store_init(const struct slot_store_cb *cb) {
  int err = settings_subsys_init();

  if (err != 0) {
    printk("Flash: area de gravacoes ilegivel (%d); formatando...\n", err);
    err = format_partition();
    if (err == 0) {
      err = settings_subsys_init();
    }
    if (err != 0) {
      return err;
    }
    printk("Flash: area formatada (gravacoes anteriores perdidas)\n");
  }
  cbs = cb;
  loaded = 0;
  err = settings_load_subtree(STORE_ROOT);
  return err != 0 ? err : loaded;
}

/* A chave antiga do mesmo slot sai, para nao competir com a nova na
 * proxima partida. */
static void drop_legacy(int dev, int slot) {
  char key[24];

  if (cbs != NULL && dev == cbs->legacy_device) {
    snprintk(key, sizeof(key), STORE_ROOT "/s%d", slot);
    settings_delete(key);
  }
}

int slot_store_save(int dev, int slot, const struct ir_seq *seq) {
  uint8_t buf[IR_SEQ_STORE_MAX];
  char key[24];
  int len = ir_seq_pack(seq, buf, sizeof(buf));

  if (len == 0) {
    return -EINVAL;
  }
  drop_legacy(dev, slot);
  snprintk(key, sizeof(key), STORE_ROOT "/d%ds%d", dev, slot);
  return settings_save_one(key, buf, len);
}

int slot_store_save_raw(int dev, int slot, const struct ir_raw *raw) {
  char key[24];
  int len = ir_raw_pack(raw, store_buf, sizeof(store_buf));

  if (len == 0) {
    return -EINVAL;
  }
  drop_legacy(dev, slot);
  snprintk(key, sizeof(key), STORE_ROOT "/d%ds%d", dev, slot);
  return settings_save_one(key, store_buf, len);
}

int slot_store_erase(int dev, int slot) {
  char key[24];

  drop_legacy(dev, slot);
  snprintk(key, sizeof(key), STORE_ROOT "/d%ds%d", dev, slot);
  return settings_delete(key);
}

int slot_store_save_device(int dev) {
  uint8_t d = (uint8_t)dev;

  return settings_save_one(STORE_ROOT "/dev", &d, 1);
}
```

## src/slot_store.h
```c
/* Gravacoes na flash, pelo subsistema settings com NVS.
 *
 * Chaves (particao zephyr,settings-partition da placa, storage_partition):
 *   remote/d<D>s<S>  gravacao do slot S do aparelho D (ir_seq_pack, ou
 *                    ir_raw_pack para gravacao crua; o 1o byte diz qual)
 *   remote/dev       aparelho escolhido por ultimo (1 byte)
 *   remote/s<S>      formato antigo (um aparelho so): vai para o aparelho
 *                    "livre" ao carregar
 */
#ifndef SLOT_STORE_H
#define SLOT_STORE_H

#include "ir_seq.h"

struct slot_store_cb {
  int num_devices;
  int max_slots;
  int legacy_device; /* aparelho que recebe as chaves remote/s<S> */
  void (*on_slot)(int dev, int slot, const struct ir_seq *seq);
  void (*on_raw)(int dev, int slot, const struct ir_raw *raw);
  void (*on_device)(int dev);
};

/* Inicia o settings e carrega tudo. Devolve quantas gravacoes foram
 * carregadas, ou um erro negativo (tudo continua so na RAM). */
int slot_store_init(const struct slot_store_cb *cb);

/* Grava a sequencia do slot. Devolve 0 ou um erro negativo. */
int slot_store_save(int dev, int slot, const struct ir_seq *seq);

/* Grava uma gravacao crua (ate ~2 KB). */
int slot_store_save_raw(int dev, int slot, const struct ir_raw *raw);

/* Apaga a gravacao do slot (volta ao codigo de fabrica, se houver). */
int slot_store_erase(int dev, int slot);

/* Lembra o aparelho escolhido. */
int slot_store_save_device(int dev);

#endif /* SLOT_STORE_H */
```
